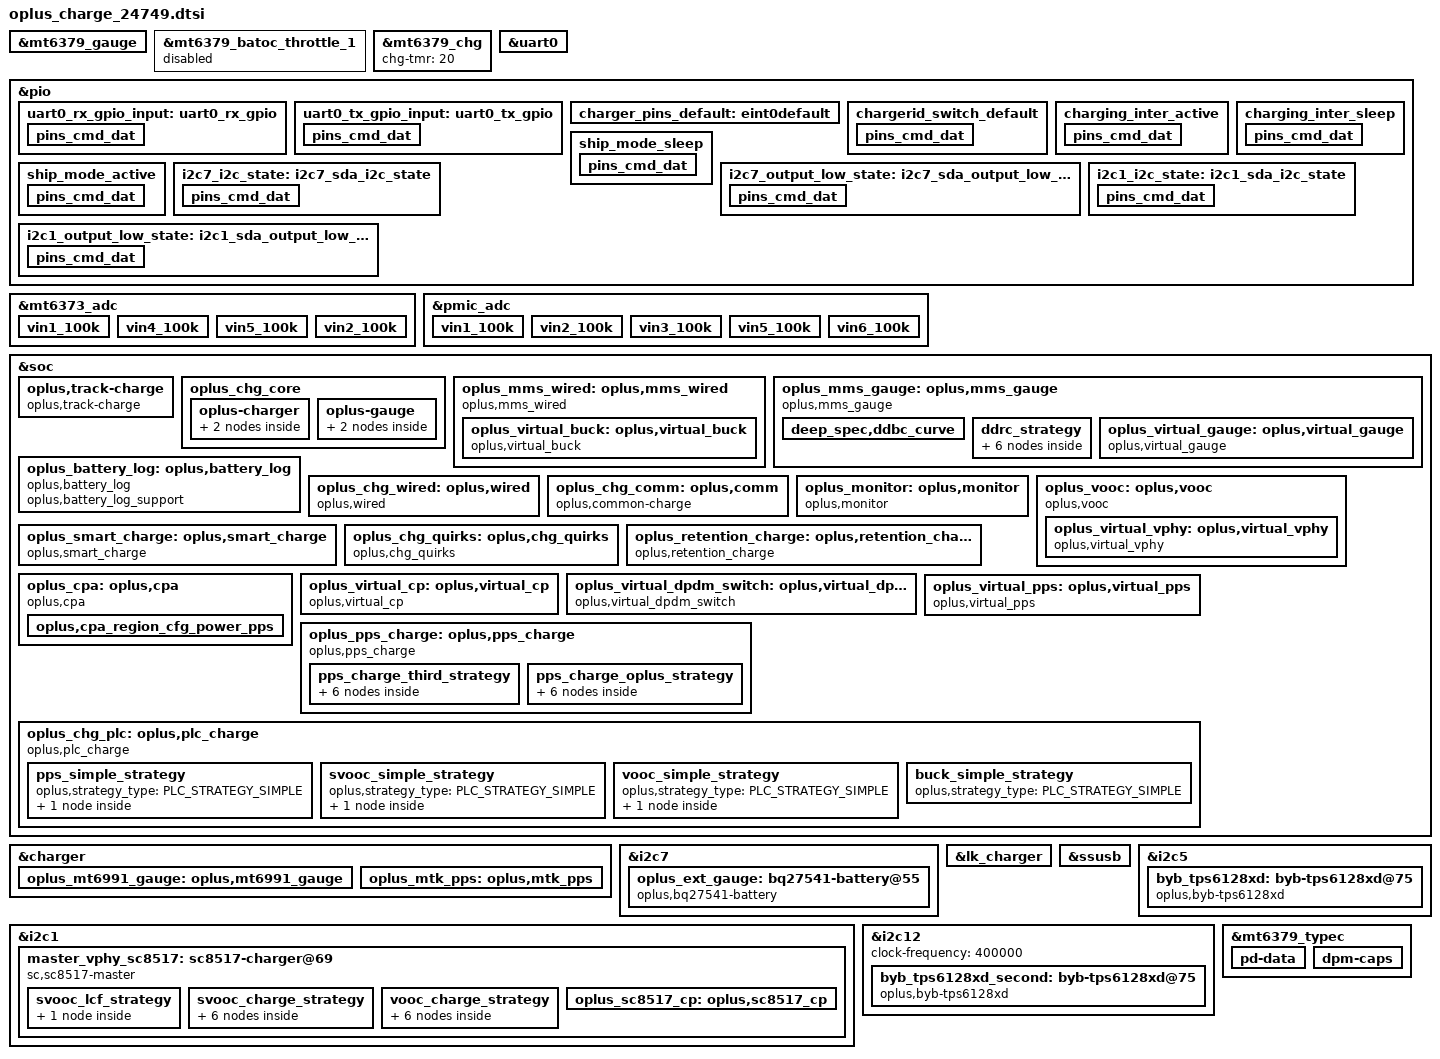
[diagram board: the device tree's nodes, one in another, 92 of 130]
// SPDX-License-Identifier: GPL-2.0-only
/*
* Copyright (C) 2021-2020 Oplus. All rights reserved.
*/
#include <dt-bindings/iio/mt635x-auxadc.h>
#include <dt-bindings/iio/adc/mediatek,mt6379_auxadc.h>  //???
#include <dt-bindings/pinctrl/mt6989-pinfunc.h>
#include <dt-bindings/pinctrl/mt65xx.h>
//#include "oplus_charge_22113.h"
#include "oplus_chg.h"

/* charge start */
//&regulator_vibrator{
//	status = "disabled";
//};

&mt6379_gauge {
	disable-mtkbattery = <(1)>;
	charger = <&mt6379_chg>;
};

&mt6379_batoc_throttle_1 {
	/* disable the batoc to avoid the issue of bat_oc interrup when the master BTB not connected */
	status = "disabled";
};

&mt6379_chg {
	chg-tmr = <20>;
};

&uart0 {
	pinctrl-names = "uart0_rx_gpio", "uart0_tx_gpio";
	pinctrl-0 = <&uart0_rx_gpio_input>;
	pinctrl-1 = <&uart0_tx_gpio_input>;
	status = "okay";

	txpin = <203>;
	rxpin = <204>;
};

&pio {
	uart0_rx_gpio_input: uart0_rx_gpio {
		pins_cmd_dat {
			pinmux = <PINMUX_GPIO204__FUNC_GPIO204>;
			input-enable;
			bias-disable;
		};
	};

	uart0_tx_gpio_input: uart0_tx_gpio {
		pins_cmd_dat {
			pinmux = <PINMUX_GPIO203__FUNC_GPIO203>;
			input-enable;
			bias-disable;
		};
	};
};

/* mt6373_adc is defined in mt6373.dtsi */
&mt6373_adc {
	vin1_100k {
		channel = <AUXADC_VIN1>;
		pures = <ADC_PURES_100K>;
	};
	vin4_100k {
		channel = <AUXADC_VIN4>;
		pures = <ADC_PURES_100K>;
	};
	vin5_100k {
		channel = <AUXADC_VIN5>;
		pures = <ADC_PURES_100K>;
	};
	vin2_100k {
		channel = <AUXADC_VIN2>;
		pures = <ADC_PURES_100K>;
	};
};

/* pmic_adc is defined in mt6363.dtsi */
&pmic_adc {
	vin1_100k {
		channel = <AUXADC_VIN1>;
		pures = <ADC_PURES_100K>;
	};
	vin2_100k {
		channel = <AUXADC_VIN2>;
		pures = <ADC_PURES_100K>;
	};
	vin3_100k {
		channel = <AUXADC_VIN3>;
		pures = <ADC_PURES_100K>;
	};
	vin5_100k {
		channel = <AUXADC_VIN5>;
		pures = <ADC_PURES_100K>;
	};
	vin6_100k {
		channel = <AUXADC_VIN6>;
		pures = <ADC_PURES_100K>;
	};
};

/* refer to udon oplus-chg-22803 */
&soc {
	oplus,track-charge {
		compatible = "oplus,track-charge";
		track,fast_chg_break_t_thd = <1400>;
		track,general_chg_break_t_thd = <300>;
		track,voocphy_type = <TRACK_AP_SINGLE_CP_VOOCPHY>;
		track,wired_max_power = <120000>;
		track,wired_fast_chg_scheme = <0>;
	};

};

&pio {
	charger_pins_default: eint0default {
	};

	chargerid_switch_default: chargerid_switch_default {
		pins_cmd_dat {
			pinmux = <PINMUX_GPIO81__FUNC_GPIO81>;
			bias-disable;
		};
	};

	charging_inter_active: charging_inter_active {
		pins_cmd_dat {
			pinmux = <PINMUX_GPIO83__FUNC_GPIO83>;
			input-enable;
			bias-pull-up;
		};
	};

	charging_inter_sleep: charging_inter_sleep {
		pins_cmd_dat {
			pinmux = <PINMUX_GPIO83__FUNC_GPIO83>;
			input-enable;
			bias-pull-up;
		};
	};

	ship_mode_sleep: ship_mode_sleep {
		pins_cmd_dat {
			pinmux = <PINMUX_GPIO216__FUNC_GPIO216>;
			output-low;
		};
	};

	ship_mode_active: ship_mode_active {
		pins_cmd_dat {
			pinmux = <PINMUX_GPIO216__FUNC_GPIO216>;
			output-high;
		};
	};
};

&soc {
	oplus_chg_core {
		oplus,chg_framework_v2;
		oplus,smart_charging_screenoff;
		oplus,chg_spec_version = <OPLUS_CHG_SPEC_VER_V3P7>;
		oplus,eco_region_list = /bits/ 8 <0x44>;
		oplus,common-charge-icl-support;

		oplus-charger {
			mtk_6991_groups: oplus,mtk_6991-groups {
				functions = <
					OPLUS_IC_FUNC_INIT
					OPLUS_IC_FUNC_EXIT
					OPLUS_IC_FUNC_REG_DUMP
					OPLUS_IC_FUNC_SMT_TEST
					OPLUS_IC_FUNC_BUCK_INPUT_PRESENT
					OPLUS_IC_FUNC_BUCK_INPUT_SUSPEND
					OPLUS_IC_FUNC_BUCK_INPUT_IS_SUSPEND
					OPLUS_IC_FUNC_BUCK_OUTPUT_SUSPEND
					OPLUS_IC_FUNC_BUCK_OUTPUT_IS_SUSPEND
					OPLUS_IC_FUNC_BUCK_SET_ICL
					OPLUS_IC_FUNC_BUCK_GET_ICL
					OPLUS_IC_FUNC_BUCK_SET_FCC
					OPLUS_IC_FUNC_BUCK_SET_FV
					OPLUS_IC_FUNC_BUCK_SET_ITERM
					OPLUS_IC_FUNC_BUCK_GET_INPUT_CURR
					OPLUS_IC_FUNC_BUCK_GET_INPUT_VOL
					OPLUS_IC_FUNC_OTG_BOOST_ENABLE
					OPLUS_IC_FUNC_BUCK_GET_CC_ORIENTATION
					OPLUS_IC_FUNC_BUCK_GET_CHARGER_TYPE
					OPLUS_IC_FUNC_BUCK_RERUN_BC12
					OPLUS_IC_FUNC_BUCK_QC_DETECT_ENABLE
					OPLUS_IC_FUNC_BUCK_SET_QC_CONFIG
					OPLUS_IC_FUNC_BUCK_SET_PD_CONFIG
					OPLUS_IC_FUNC_GET_SHUTDOWN_SOC
					OPLUS_IC_FUNC_BACKUP_SOC
					OPLUS_IC_FUNC_GET_TYPEC_MODE
					OPLUS_IC_FUNC_SET_TYPEC_MODE
					OPLUS_IC_FUNC_GET_TYPEC_ROLE
					OPLUS_IC_FUNC_GET_OTG_ENABLE
					OPLUS_IC_FUNC_BUCK_GET_HW_DETECT
					OPLUS_IC_FUNC_SET_USB_DISCHG_ENABLE
					OPLUS_IC_FUNC_GET_USB_DISCHG_STATUS
					OPLUS_IC_FUNC_IS_OPLUS_SVID
					OPLUS_IC_FUNC_BUCK_GET_USB_BTB_TEMP
					OPLUS_IC_FUNC_BUCK_GET_BATT_BTB_TEMP
					OPLUS_IC_FUNC_BUCK_SHIPMODE_ENABLE
					OPLUS_IC_FUNC_BUCK_SET_AICL_POINT
					OPLUS_IC_FUNC_SET_OTG_BOOST_CURR_LIMIT
					OPLUS_IC_FUNC_SET_OTG_BOOST_VOL
					OPLUS_IC_FUNC_BUCK_GET_FV
					OPLUS_IC_FUNC_BUCK_GET_TYPEC_STATE
					OPLUS_IC_FUNC_WLS_BOOST_ENABLE
					OPLUS_IC_FUNC_SET_WLS_BOOST_VOL
					OPLUS_IC_FUNC_SET_WLS_BOOST_CURR_LIMIT
					OPLUS_IC_FUNC_BUCK_WLS_INPUT_SUSPEND
					OPLUS_IC_FUNC_BUCK_SET_WLS_ICL
					OPLUS_IC_FUNC_BUCK_GET_WLS_ICL
					OPLUS_IC_FUNC_BUCK_GET_WLS_INPUT_CURR
					OPLUS_IC_FUNC_BUCK_GET_WLS_INPUT_VOL
					OPLUS_IC_FUNC_BUCK_WLS_AICL_ENABLE
					OPLUS_IC_FUNC_BUCK_WLS_AICL_RERUN
					OPLUS_IC_FUNC_BUCK_DIS_INSERT_DETECT
					OPLUS_IC_FUNC_BUCK_GET_USB_AICL_ENHANCE
				>;
				virqs = <
					OPLUS_IC_VIRQ_ERR
					OPLUS_IC_VIRQ_CC_DETECT
					OPLUS_IC_VIRQ_PLUGIN
					OPLUS_IC_VIRQ_CC_CHANGED
					OPLUS_IC_VIRQ_CHG_TYPE_CHANGE
					OPLUS_IC_VIRQ_OTG_ENABLE
					OPLUS_IC_VIRQ_SVID
					OPLUS_IC_VIRQ_TYPEC_STATE
				>;
			};
			byb_tps6128xd_groups: oplus,byb-tps6128xd-groups {

				functions = <
					OPLUS_IC_FUNC_INIT
					OPLUS_IC_FUNC_EXIT
					OPLUS_IC_FUNC_REG_DUMP
				>;
				virqs = <
					OPLUS_IC_VIRQ_ERR
				>;
			};
		};

		oplus-gauge {
			bq27541_groups: oplus,bq27541_groups {
				functions = <
					OPLUS_IC_FUNC_INIT
					OPLUS_IC_FUNC_EXIT
					OPLUS_IC_FUNC_REG_DUMP
					OPLUS_IC_FUNC_SMT_TEST
					OPLUS_IC_FUNC_GAUGE_GET_BATT_VOL
					OPLUS_IC_FUNC_GAUGE_GET_BATT_MAX
					OPLUS_IC_FUNC_GAUGE_GET_BATT_MIN
					OPLUS_IC_FUNC_GAUGE_GET_BATT_CURR
					OPLUS_IC_FUNC_GAUGE_GET_BATT_TEMP
					OPLUS_IC_FUNC_GAUGE_GET_BATT_SOC
					OPLUS_IC_FUNC_GAUGE_GET_BATT_FCC
					OPLUS_IC_FUNC_GAUGE_GET_BATT_CC
					OPLUS_IC_FUNC_GAUGE_GET_BATT_RM
					OPLUS_IC_FUNC_GAUGE_GET_BATT_SOH
					OPLUS_IC_FUNC_GAUGE_GET_BATT_AUTH
					OPLUS_IC_FUNC_GAUGE_GET_BATT_HMAC
					OPLUS_IC_FUNC_GAUGE_SET_BATT_FULL
					OPLUS_IC_FUNC_GAUGE_UPDATE_DOD0
					OPLUS_IC_FUNC_GAUGE_UPDATE_SOC_SMOOTH
					OPLUS_IC_FUNC_GAUGE_GET_CB_STATUS
					OPLUS_IC_FUNC_GAUGE_GET_BATT_NUM
					OPLUS_IC_FUNC_GAUGE_GET_DEVICE_TYPE
					OPLUS_IC_FUNC_GAUGE_GET_DEVICE_TYPE_FOR_VOOC
					OPLUS_IC_FUNC_GAUGE_GET_BATT_FCC
					OPLUS_IC_FUNC_GAUGE_GET_BATT_FC
					OPLUS_IC_FUNC_GAUGE_GET_BATT_QM
					OPLUS_IC_FUNC_GAUGE_GET_BATT_PD
					OPLUS_IC_FUNC_GAUGE_GET_BATT_RCU
					OPLUS_IC_FUNC_GAUGE_GET_BATT_RCF
					OPLUS_IC_FUNC_GAUGE_GET_BATT_FCU
					OPLUS_IC_FUNC_GAUGE_GET_BATT_FCF
					OPLUS_IC_FUNC_GAUGE_GET_BATT_SOU
					OPLUS_IC_FUNC_GAUGE_GET_BATT_DO0
					OPLUS_IC_FUNC_GAUGE_GET_BATT_DOE
					OPLUS_IC_FUNC_GAUGE_GET_BATT_TRM
					OPLUS_IC_FUNC_GAUGE_GET_BATT_PC
					OPLUS_IC_FUNC_GAUGE_GET_BATT_QS
					OPLUS_IC_FUNC_GAUGE_IS_SUSPEND
					OPLUS_IC_FUNC_GAUGE_GET_BCC_PARMS
					OPLUS_IC_FUNC_GAUGE_FASTCHG_UPDATE_BCC_PARMS
					OPLUS_IC_FUNC_GAUGE_GET_PREV_BCC_PARMS
					OPLUS_IC_FUNC_GAUGE_SET_BCC_PARMS
					OPLUS_IC_FUNC_GAUGE_SET_PROTECT_CHECK
					OPLUS_IC_FUNC_GAUGE_GET_AFI_UPDATE_DONE
					OPLUS_IC_FUNC_GAUGE_CHECK_RESET
					OPLUS_IC_FUNC_GAUGE_SET_RESET
					OPLUS_IC_FUNC_GAUGE_GET_DEVICE_TYPE_FOR_BCC
					OPLUS_IC_FUNC_GAUGE_GET_DOD0
					OPLUS_IC_FUNC_GAUGE_GET_DOD0_PASSED_Q
					OPLUS_IC_FUNC_GAUGE_GET_QMAX
					OPLUS_IC_FUNC_GAUGE_GET_QMAX_PASSED_Q
					OPLUS_IC_FUNC_GAUGE_GET_REG_INFO
					OPLUS_IC_FUNC_GAUGE_GET_CALIB_TIME
					OPLUS_IC_FUNC_GAUGE_GET_DEEP_DISCHG_COUNT
					OPLUS_IC_FUNC_GAUGE_SET_DEEP_DISCHG_COUNT
					OPLUS_IC_FUNC_GAUGE_GET_DEEP_TERM_VOLT
					OPLUS_IC_FUNC_GAUGE_SET_DEEP_TERM_VOLT
					OPLUS_IC_FUNC_GAUGE_SET_SILI_SPARE_POWER
					OPLUS_IC_FUNC_GAUGE_GET_SILI_SIMULATE_TERM_VOLT
					OPLUS_IC_FUNC_GAUGE_GET_SILI_IC_ALG_TERM_VOLT
					OPLUS_IC_FUNC_GAUGE_SET_SILI_IC_ALG_CFG
					OPLUS_IC_FUNC_GAUGE_GET_SILI_IC_ALG_DSG_ENABLE
					OPLUS_IC_FUNC_GAUGE_SET_SILI_IC_ALG_TERM_VOLT
					OPLUS_IC_FUNC_GAUGE_GET_SILI_ALG_APPLICATION_INFO
					OPLUS_IC_FUNC_GAUGE_GET_SILI_LIFETIME_STATUS
					OPLUS_IC_FUNC_GAUGE_GET_SILI_LIFETIME_INFO
					OPLUS_IC_FUNC_GAUGE_SET_CALIB_TIME
					OPLUS_IC_FUNC_GAUGE_SET_LAST_CC
					OPLUS_IC_FUNC_GAUGE_GET_LAST_CC
					OPLUS_IC_FUNC_GAUGE_GET_BATT_SN
					OPLUS_IC_FUNC_GAUGE_GET_MANU_DATE
					OPLUS_IC_FUNC_GAUGE_GET_FIRST_USAGE_DATE
					OPLUS_IC_FUNC_GAUGE_SET_FIRST_USAGE_DATE
					OPLUS_IC_FUNC_GAUGE_GET_UI_CC
					OPLUS_IC_FUNC_GAUGE_SET_UI_CC
					OPLUS_IC_FUNC_GAUGE_GET_UI_SOH
					OPLUS_IC_FUNC_GAUGE_SET_UI_SOH
					OPLUS_IC_FUNC_GAUGE_GET_USED_FLAG
					OPLUS_IC_FUNC_GAUGE_SET_USED_FLAG
					OPLUS_IC_FUNC_GAUGE_SET_SEAL_FLAG
					OPLUS_IC_FUNC_GAUGE_GET_DEC_FG_TYPE
					OPLUS_IC_FUNC_GAUGE_GET_DEC_CV_SOH
					OPLUS_IC_FUNC_GAUGE_SET_VCT
					OPLUS_IC_FUNC_GAUGE_GET_VCT
					OPLUS_IC_FUNC_GAUGE_GET_GAUGE_R_INFO
				>;
				virqs = <
					OPLUS_IC_VIRQ_ERR
					OPLUS_IC_VIRQ_OFFLINE
					OPLUS_IC_VIRQ_RESUME
				>;
			};

			mt6991_gauge_groups: oplus,mt6991_gauge_groups {
				functions = <
					OPLUS_IC_FUNC_INIT
					OPLUS_IC_FUNC_EXIT
					OPLUS_IC_FUNC_GAUGE_GET_SUBBOARD_TEMP
				>;
				virqs = <
					OPLUS_IC_VIRQ_ERR
				>;
			};
		};
	};
};

&charger {
	io-channels = <&pmic_adc (ADC_PURES_100K_MASK | AUXADC_VIN5)>,
			<&pmic_adc (ADC_PURES_100K_MASK | AUXADC_VIN6)>,
			<&pmic_adc (ADC_PURES_100K_MASK | AUXADC_VIN1)>,
			<&pmic_adc (ADC_PURES_100K_MASK | AUXADC_VIN2)>,
			<&mt6373_adc AUXADC_VIN2>;
	io-channel-names = "master_cp_temp", "auxadc6_usb_btb_temp",
			   "auxadc1-ntc_sub_bat_tem",
			   "auxadc5_batt_btb_temp", "slave_cp_temp";

	pinctrl-names = "default";
	pinctrl-0 = <&charger_pins_default>;
	oplus,support_ntc_01c_precision;
	oplus,support_subboard_ntc;
	max_charger_voltage = <15000000>;
	oplus,usb_aicl_enhance;
	oplus,low_batt_otg_boost_curr_ua = <500000>;

	oplus,ic_type = <OPLUS_CHG_IC_BUCK>;
	oplus,ic_index = <0>;

	oplus_mt6991_gauge: oplus,mt6991_gauge {
		oplus,ic_type = <OPLUS_CHG_IC_GAUGE>;
		oplus,ic_index = <1>;
	};
};
&i2c7 {
	status = "okay";
	clock-frequency = <100000>;

	oplus_ext_gauge: bq27541-battery@55 {
		status = "okay";
		compatible = "oplus,bq27541-battery";
		reg = <0x55 0>;
		qcom,modify-soc-smooth;
		qcom,modify-soc-calibration;
		oplus,remove_iterm_taper;
		qcom,batt_bq28z610; /* TODO: maybe need update.*/
		oplus,fcc_too_small_check_support;
		qcom,sha1_key_index = <1>;
		oplus,batt_num = <2>;
		oplus,ic_type = <OPLUS_CHG_IC_GAUGE>;
		oplus,ic_index = <0>;
		oplus,bq28z610_afi_buf = /bits/ 8 <
		/* checksum data_len data+ */
			0xD8 0x04 0xf4 0x46 0xED 0x00 /* Charge Term Taper Current 217mA */
			0x24 0x03 0x90 0x45 0x06 /* MIN_RES_POINTS 6 */
			0x24 0x03 0x91 0x45 0x05 /* RA_MAX_DELTA 5 */
			0xd8 0x03 0xe8 0x45 0xfa /* SOH_LOAD_RATE 250 */
			0x2 0x04 0x94 0x45 0x25 0xff /* RES_PARA_FILTER 65317 */
			0x3d 0x04 0x96 0x45 0xed 0xfa /* RA_PARA_FILTER 64237 */
			0xeb 0x03 0x89 0x45 0x46 /* MIN_DOD_RES 70 */
			0x73 0x04 0x8e 0x45 0xb6 0x3 /* RA_PARA_FILTER 950 */
		>;
		};
	};

&lk_charger {
	is_support_mt6379;
	charger_by_bidirection;
	support_external_gauge_bq28z610;
	external_gauge_type = <EXTERNAL_GAUGE_TYPE_BQ28Z719>;
	support_tuv_authentication;
	high-temp-scheme;
	support_sdp_screenoff;
	use_extern_gauge;
	sub_board_temp_support;
	over_high_temp_thr = <60>;
	sub_board_adc_channel = <18>; /* AUXADC_VIN1 */
	sub_board_adc_pull_up_voltage = <1840>;
	support_battery_type = <7>;
	batt_num = <2>;
	support_quickboot_charge;

	/* mt6991 start */
	led-brightness = <102>;
	/* mt6991, such as max_charger_voltage to max-charger-voltage */
	max-charger-voltage = <15000000>;
	boot-battery-voltage = <3350000>;
	usb-charger-current = <500000>;
	ac-charger-current = <2050000>;
	ac-charger-input-current = <1500000>;
	non-std-ac-charger-current = <750000>;
	charging-host-charger-current = <1500000>;
	ta-ac-charger-current = <1500000>;
	pd-charger-current = <500000>;
	/* mt6991 end */
	/* for silicon battery */
	is_silicon_battery;
	max-term-voltage-mv = <3300>;
	min-term-voltage-mv = <3000>;
	dcp-boot-thd-inc-mv = <(-100)>;
	cdp-boot-thd-inc-mv = <(50)>;
	sdp-boot-thd-inc-mv = <(50)>;
	wls-boot-thd-inc-mv = <(50)>;
	nochg-boot-thd-inc-mv = <(50)>;
	max-boot-thd-mv = <(3350)>;
	min-boot-thd-mv = <(3150)>;
	dcp-max-boot-thd-mv = <(3350)>;
	dcp-min-boot-thd-mv = <(3050)>;
	prechg1-thd-mv = <3000>;
	prechg1-current-ma = <500>;/* dual-cell configuration value is twice the ibat-ma */
	temp-low-inc1 = <500>; /* < -20 */
	temp-low-inc2 = <500>; /* -20 ~ -10 */
	temp-low-inc3 = <500>; /* -10 ~ 0 */
	temp-low-inc4 = <100>; /* 0 ~ 20 */
	temp-low-inc5 = <0>; /* > 20 */
	/* silicon battery end */
};

&i2c7 {
	pinctrl-names = "i2c-state", "output-low-state";
	pinctrl-0 = <&i2c7_i2c_state>;
	pinctrl-1 = <&i2c7_output_low_state>;
};
&pio {
	i2c7_i2c_state: i2c7_sda_i2c_state {
		pins_cmd_dat {
			pinmux = <PINMUX_GPIO120__FUNC_SCL7>,
			<PINMUX_GPIO121__FUNC_SDA7>;
			bias-pull-up;
		};
	};
	i2c7_output_low_state: i2c7_sda_output_low_state {
		pins_cmd_dat {
			pinmux = <PINMUX_GPIO120__FUNC_GPIO120>,
			<PINMUX_GPIO121__FUNC_GPIO121>;
			output-low;
		};
	};
};

/* for pd common charger */
&ssusb {
		usb-psy-name = "mtk-master-charger";
		typec-name = "rt-pd-manager";
		typec-port-name = "port0";
};

&i2c5 {
		mediatek,fifo-use-polling;
		mediatek,request-cpu-qos;
};

&soc {
	oplus_mms_wired: oplus,mms_wired {
		compatible = "oplus,mms_wired";
		oplus,buck_ic = <&oplus_virtual_buck>;
		oplus,voocphy_ic = <&oplus_virtual_vphy>;

		oplus,adc_info_name = "100k_1840mv";
		oplus_spec,usbtemp_batttemp_gap = <12>;
		high-temp-scheme;

		/* support for V2.0 usbtemp protect. */
		oplus,support_usbtemp_protect_v2;
		oplus_spec,usbtemp_batt_temp_low = <50>;
		oplus_spec,usbtemp_batt_temp_high = <50>;
		oplus_spec,usbtemp_batt_temp_over_hot = <60>;
		oplus_spec,usbtemp_ntc_temp_low = <57>;
		oplus_spec,usbtemp_ntc_temp_high = <69>;
		oplus_spec,usbtemp_temp_gap_low_with_batt_temp = <7>;
		oplus_spec,usbtemp_temp_gap_with_batt_temp_in_over_hot = <15>;
		oplus_spec,usbtemp_temp_gap_high_with_batt_temp = <12>;
		oplus_spec,usbtemp_temp_gap_low_without_batt_temp = <12>;
		oplus_spec,usbtemp_temp_gap_high_without_batt_temp = <24>;
		oplus_spec,usbtemp_rise_fast_temp_low = <3>;
		oplus_spec,usbtemp_rise_fast_temp_high = <3>;
		oplus_spec,usbtemp_rise_fast_temp_count_low = <30>;
		oplus_spec,usbtemp_rise_fast_temp_count_high = <20>;
		oplus_spec,usbtemp_cool_down_ntc_low = <54>;
		oplus_spec,usbtemp_cool_down_ntc_high = <65>;
		oplus_spec,usbtemp_cool_down_gap_low = <12>;
		oplus_spec,usbtemp_cool_down_gap_high = <20>;
		oplus_spec,usbtemp_cool_down_recover_ntc_low = <48>;
		oplus_spec,usbtemp_cool_down_recover_ntc_high = <60>;
		oplus_spec,usbtemp_cool_down_recover_gap_low = <6>;
		oplus_spec,usbtemp_cool_down_recover_gap_high = <15>;
		oplus_spec,usbtemp_otg_cc_boot_current_limit = <1300000>;

		oplus_virtual_buck: oplus,virtual_buck {
			compatible = "oplus,virtual_buck";
			oplus,buck_ic = <&charger &byb_tps6128xd &byb_tps6128xd_second>;
			oplus,buck_ic_index = <0 1 2>;
			oplus,buck_ic_current_ratio = <100 0 0>;
			oplus,buck_ic_connect = <OPLUS_CHG_IC_CONNECT_PARALLEL>;
			oplus,main_charger = <0>;
			oplus,buck_ic_func_group = <&mtk_6991_groups &byb_tps6128xd_groups &byb_tps6128xd_groups>;

			oplus,ic_type = <OPLUS_CHG_IC_VIRTUAL_BUCK>;
			oplus,ic_index = <0>;

			/* SHIP_MODE_ON */
			oplus,ship-gpio = <&pio 216 0x00>;

			pinctrl-names = "ship_active", "ship_sleep";
			pinctrl-0 = <&ship_mode_active>;
			pinctrl-1 = <&ship_mode_sleep>;

			io-channels = <&mt6373_adc AUXADC_VIN4>, <&mt6373_adc AUXADC_VIN5>;
			io-channel-names = "usb_temp_adc_l", "usb_temp_adc_r";

			oplus,uart_tx-gpio = <&pio 203 0x00>;
			oplus,uart_rx-gpio = <&pio 204 0x00>;
		};
	};

	oplus_mms_gauge: oplus,mms_gauge {
		compatible = "oplus,mms_gauge";
		oplus,gauge_ic = <&oplus_virtual_gauge>;
		oplus,topic-update-interval = <10000>;
		oplus,support_subboard_ntc;

		deep_spec,support;
		deep_spec,uv_thr = <3000>;
		deep_spec,count_thr = <50>;
		deep_spec,vbat_soc = <20>;
		deep_spec,count_step = <0 10 0
					350 12 1
					450 15 2
					530 20 3>;
		deep_spec,term_coeff = <3000 800 3
					3050 900 5
					3060 900 5
					3100 950 7
					3150 950 7
					3200 1050 9
					3300 1200 10>;
		deep_spec,ddrc_strategy_name = "ddrc_curve";
		deep_spec,volt_step = <20>;
		deep_spec,ddbc_curve {
			oplus,temp_type = <OPLUS_STRATEGY_USE_BATT_TEMP>;
			oplus,temp_range = <(-100) 50 200>;
			deep_spec,ddbc_temp_cold =   <500   3250 5
						      10000 3200 2>;
			deep_spec,ddbc_temp_cool =   <500   3250 5
						      10000 3200 2>;
			deep_spec,ddbc_temp_normal = <500   3350 5
						      10000 3300 2>;
			deep_spec,ddbc_temp_warm =   <500   3350 5
						      10000 3300 2>;
		};
		ddrc_strategy {
			oplus,temp_type = <OPLUS_STRATEGY_USE_BATT_TEMP>;
			oplus,ratio_range = <20 30 50 70 90>;
			oplus,temp_range = <(-50) 100 350>;
			strategy_ratio_range_min { /* 0 ~ 0.2 */
				strategy_temp_cold =	<0    3000 3060 0
							 400  3000 3060 1
							 800  3000 3060 2
							 1200 3100 3100 3
							 1600 3200 3200 4
							 2000 3300 3300 5>;
				strategy_temp_cool =	<0    3000 3060 0
							 15   3000 3060 1
							 500  3000 3060 2
							 1000 3100 3100 3
							 1500 3200 3200 4
							 2000 3300 3300 5>;
				strategy_temp_normal =	<0    3150 3150 0
							 15   3150 3150 1
							 500  3150 3150 2
							 1000 3200 3200 3
							 1500 3300 3300 4>;
				strategy_temp_warm =	<0    3150 3150 0
							 15   3150 3150 1
							 500  3150 3150 2
							 1000 3200 3200 3
							 1500 3300 3300 4>;
			};
			strategy_ratio_range_low { /* 0.2 ~ 0.3 */
				strategy_temp_cold =	<0    3000 3060 0
							 300  3000 3060 1
							 600  3000 3060 2
							 900  3100 3100 3
							 1200 3200 3200 4
							 1600 3300 3300 5>;
				strategy_temp_cool =	<0    3000 3060 0
							 15   3000 3060 1
							 400  3000 3060 2
							 800  3100 3100 3
							 1200 3200 3200 4
							 1600 3300 3300 5>;
				strategy_temp_normal =	<0    3150 3150 0
							 15   3150 3150 1
							 400  3150 3150 2
							 800  3200 3200 3
							 1200 3300 3300 4>;
				strategy_temp_warm =	<0    3150 3150 0
							 15   3150 3150 1
							 400  3150 3150 2
							 800  3200 3200 3
							 1200 3300 3300 4>;
			};
			strategy_ratio_range_mid_low { /* 0.3 ~ 0.5 */
				strategy_temp_cold =	<0    3000 3060 0
							 200  3000 3060 1
							 400  3000 3060 2
							 600  3100 3100 3
							 900  3200 3200 4
							 1200  3300 3300 5>;
				strategy_temp_cool =	<0    3000 3060 0
							 15   3000 3060 1
							 300  3000 3060 2
							 600  3100 3100 3
							 900  3200 3200 4
							 1200  3300 3300 5>;
				strategy_temp_normal =	<0    3150 3150 0
							 15   3150 3150 1
							 300  3150 3150 2
							 600  3200 3200 3
							 900  3300 3300 4>;
				strategy_temp_warm =	<0    3150 3150 0
							 15   3150 3150 1
							 300  3150 3150 2
							 600  3200 3200 3
							 900  3300 3300 4>;
			};
			strategy_ratio_range_mid { /* 0.5 ~ 0.7 */
				strategy_temp_cold =	<0    3000 3060 0
							 100  3000 3060 1
							 300  3000 3060 2
							 500  3100 3100 3
							 700  3200 3200 4
							 900  3300 3300 5>;
				strategy_temp_cool =	<0   3000 3060 0
							 100 3000 3060 1
							 300 3100 3100 2
							 600 3200 3200 3
							 900 3300 3300 4>;
				strategy_temp_normal =	<0   3150 3150 0
							 100 3150 3150 1
							 300 3200 3200 2
							 600 3300 3300 3>;
				strategy_temp_warm =	<0   3150 3150 0
							 100 3150 3150 1
							 300 3200 3200 2
							 600 3300 3300 3>;
			};
			strategy_ratio_range_mid_high { /* 0.7 ~ 0.9 */
				strategy_temp_cold =	<0    3000 3060 0
							 50   3000 3060 1
							 100  3000 3060 2
							 150  3100 3100 3
							 300  3200 3200 4
							 500  3300 3300 5>;
				strategy_temp_cool =	<0    3000 3060 0
							 50   3000 3060 1
							 100  3100 3100 2
							 150  3200 3200 3
							 300  3300 3300 4>;
				strategy_temp_normal =	<0    3150 3150 0
							 50   3150 3150 1
							 100  3200 3200 2
							 150  3300 3300 3>;
				strategy_temp_warm =	<0    3150 3150 0
							 50   3150 3150 1
							 100  3200 3200 2
							 150  3300 3300 3>;
			};
			strategy_ratio_range_high { /* 0.9 ~ 1 */
				strategy_temp_cold =	<0    3000 3060 0
							 50   3000 3060 1
							 100  3000 3060 2
							 150  3100 3100 3
							 300  3200 3200 4
							 500  3300 3300 5>;
				strategy_temp_cool =	<0    3000 3060 0
							 50   3000 3060 1
							 100  3100 3100 2
							 150  3200 3200 3
							 300  3300 3300 4>;
				strategy_temp_normal =	<0    3150 3150 0
							 50   3150 3150 1
							 100  3200 3200 2
							 150  3300 3300 3>;
				strategy_temp_warm =	<0    3150 3150 0
							 50   3150 3150 1
							 100  3200 3200 2
							 150  3300 3300 3>;
			};
		};
		oplus_virtual_gauge: oplus,virtual_gauge {
			compatible = "oplus,virtual_gauge";
			oplus,gauge_ic = <&oplus_ext_gauge &oplus_mt6991_gauge>;
			oplus,gauge_ic_index = <0 1>;
			oplus,gauge_ic_func_group = <&bq27541_groups &mt6991_gauge_groups>;
			oplus,batt_capacity_mah = <7000>;
			oplus,ic_type = <OPLUS_CHG_IC_VIRTUAL_GAUGE>;
			oplus,ic_index = <0>;
		};
	};
};

&soc {
	oplus_battery_log: oplus,battery_log {
		compatible = "oplus,battery_log";

		oplus,battery_log_support;
	};

	oplus_chg_wired: oplus,wired {
		compatible = "oplus,wired";

		oplus,vooc-support;

		oplus_spec,vbatt_pdqc_to_5v_thr = <5100>;
		oplus_spec,vbatt_pdqc_to_9v_thr = <5000>;
		oplus_spec,pd-iclmax-ma = <2000>;
		oplus_spec,qc-iclmax-ma = <2000>;
		oplus_spec,non-standard-ibatmax-ma = <500>;
		oplus_spec,input-power-mw = <
			500		/* OPLUS_WIRED_CHG_MODE_UNKNOWN */
			2500		/* OPLUS_WIRED_CHG_MODE_SDP */
			7500		/* OPLUS_WIRED_CHG_MODE_CDP */
			10000		/* OPLUS_WIRED_CHG_MODE_DCP */
			15000		/* OPLUS_WIRED_CHG_MODE_VOOC */
			13500		/* OPLUS_WIRED_CHG_MODE_QC */
			13500		/* OPLUS_WIRED_CHG_MODE_PD */
		>;
		oplus_spec,led_on-fccmax-ma = <0 602 3014 3300 3300 3300 3300 1000 0>;
		oplus_spec,fccmax-ma-lv = <
			0 602 2200 2200 2200 2200 2200 2200 0	/* OPLUS_WIRED_CHG_MODE_UNKNOWN */
			0 600  600  600  600  600  600  600  0	/* OPLUS_WIRED_CHG_MODE_SDP */
			0 602 1600 1600 1600 1600 1600 1600 0	/* OPLUS_WIRED_CHG_MODE_CDP */
			0 602 2200 2200 2200 2200 2200 2200 0	/* OPLUS_WIRED_CHG_MODE_DCP */
			0 602 3014 3300 3300 3300 3300 3300 0	/* OPLUS_WIRED_CHG_MODE_VOOC */
			0 602 2860 2860 2860 2860 2860 2860 0	/* OPLUS_WIRED_CHG_MODE_QC */
			0 602 2860 2860 2860 2860 2860 2860 0	/* OPLUS_WIRED_CHG_MODE_PD */
		>;
		oplus_spec,fccmax-ma-hv = <
			0 484  968 2200 2200 2200 2200 2200 0	/* OPLUS_WIRED_CHG_MODE_UNKNOWN */
			0 600  600  600  600  600  600  600 0	/* OPLUS_WIRED_CHG_MODE_SDP */
			0 602  1206 1600 1600 1600 1600 600 0	/* OPLUS_WIRED_CHG_MODE_CDP */
			0 602  1206 1808 2200 2200 2200 1000 0	/* OPLUS_WIRED_CHG_MODE_DCP */
			0 602  1206 1808 3014 3300 3300 1000 0	/* OPLUS_WIRED_CHG_MODE_VOOC */
			0 602  1206 1808 2860 2860 2860 1000 0	/* OPLUS_WIRED_CHG_MODE_QC */
			0 602  1206 1808 2860 2860 2860 1000 0	/* OPLUS_WIRED_CHG_MODE_PD */
		>;
		oplus_spec,cool_down_sale_pdqc_vol_mv = <9000>;
		oplus_spec,cool_down_sale_pdqc_curr_ma = <1200>;
		oplus_spec,cool_down_pdqc_vol_mv = <9000 9000 9000>;
		oplus_spec,cool_down_pdqc_curr_ma = <1200 1500 2000>;
		oplus_spec,cool_down_vooc_curr_ma = <1500 1500 2000 2500 3000 3500>;
		oplus_spec,cool_down_normal_curr_ma = <1200 1500 2000>;

		oplus_spec,vbus_ov_thr_mv = <11000 11000>;
		oplus_spec,vbus_uv_thr_mv = <4300 4300>;

		/* first data is strategy used temp type */
		oplus,vooc_strategy_name = "cgcl";
		oplus,vooc_strategy_data = <OPLUS_STRATEGY_USE_BATT_TEMP
					    0   350 3600 1 0
					    330 370 3200 2 0
					    350 440 2200 2 1>;
	};

	oplus_chg_comm: oplus,comm {
		compatible = "oplus,common-charge";
		oplus_spec,dec_step = <20>;
		oplus_spec,dec-vol-cc-full-thr = <0 400 600 800 1000 1200>;
		oplus_spec,dec-vol-fv-full-mv = <0 20 20 40 40 40>;
		oplus_spec,batt-them-thr = <(-100) 0 50 120 160 350 450 530>;
		oplus_spec,iterm-ma = <178>; /* 2220*0.05+10 */
		oplus_spec,removed_bat_decidegc = <390>; /*-39 degree*/
		oplus_spec,fv-mv = <4500 4500 4500 4500 4500 4500 4475 4130 4130>;
		oplus_spec,sw-fv-mv = <4450 4450 4450 4450 4450 4450 4425 4080 4080>;
		oplus_spec,hw-fv-inc-mv = <0 18 18 18 18 18 18 18 0>;
		oplus_spec,sw-over-fv-mv = <4510 4510 4510 4510 4510 4510 4485 4140 4140>;
		oplus_spec,sw-over-fv-dec-mv = <8>;
		oplus_spec,non-standard-sw-fv-mv = <3930>;
		oplus_spec,non-standard-fv-mv = <3980>;
		oplus_spec,non-standard-hw-fv-inc-mv = <18>;
		oplus_spec,non-standard-sw-over-fv-mv = <3990>;
		oplus_spec,non-standard-vbatdet-mv = <3680>;
		oplus_spec,wired-vbatdet-mv = <0 4200 4300 4400 4400 4400 4375 4030 0>;
		oplus_spec,wls-vbatdet-mv = <0 4210 4310 4410 4410 4410 4385 4030 0>;
		oplus_spec,fcc-gear-thr-mv = <4180>;
		oplus_spec,fcc-gear-shake-mv = <550 550 350 200 200 150 150 100 100>;
		oplus_spec,vbatt-ov-thr-mv = <4600>;

		oplus_spec,full_pre_ffc_judge;
		oplus_spec,full-pre-ffc-mv = <4495>;
		oplus_spec,ffc-temp-thr = <120 210 350 440>;
		oplus_spec,wired-ffc-step-max = <2>;
		oplus_spec,wired-ffc-fv-mv = <4590 4590>;
		oplus_spec,wired-ffc-fv-cutoff-mv = <4550 4525 4490
						     4520 4505 4475>;

		oplus_spec,wired-ffc-fcc-ma = <1100 1100 1100
					         700 700 700>;
		oplus_spec,wired-ffc-fcc-cutoff-ma = <400 400 400
						      200 200 200>;

		oplus_spec,drop_soc_2_temp_ladder = <(-50) 0 0 0 0 0 0 0 0 0>;
		oplus_spec,volt_diff_ladder_of_drop_soc_2 = <20 50 0 0 0 0 0 0 0 0>;
		oplus_spec,keep_soc_2_temp_ladder = <(-200) (-50) 0 0 0 0 0 0 0 0>;
		oplus_spec,volt_diff_ladder_of_keep_soc_2 = <10 20 30 0 0 0 0 0 0 0>;
		oplus_spec,back_rm_of_drop_soc_2 = <60>;
		oplus_spec,back_rm_of_drop_soc_1 = <60>;
		oplus_spec,load_current_of_drop_soc_2 = <500>;
		oplus_spec,load_current_of_drop_soc_1 = <1000>;
		oplus_spec,current_limit_of_drop_soc_2 = <350>;
		oplus_spec,volt_of_fast_drop_soc_1 = <3000>;
		oplus_spec,support_uisoc_low_battery_control;
		oplus_spec,support_gauge_r_track;

		oplus_spec,wls-ffc-step-max = <2>;
		oplus_spec,wls-ffc-fv-mv = <4630 4630>;
		oplus_spec,wls-ffc-fv-cutoff-mv = <4545 4545 4545
						   4545 4545 4545>;
		oplus_spec,wls-ffc-icl-ma = <1150 1150 1550
					     800  1050 1500>;
		oplus_spec,wls-ffc-fcc-ma = <1500 1500 2070
					     1050 1400 1970>;
		oplus_spec,wls-ffc-fcc-cutoff-ma = <1300 1300 1870
						    950 1300 1870>;
		oplus_spec,vbat_uv_thr_mv = <3000>;
		oplus_spec,vbat_charging_uv_thr_mv = <2900>;
		oplus_spec,vbat_charging_uv_delata_mv = <0>;

		/*If use subboard NTC as battery temp, config it as 20, otherwise 0 */
		oplus_spec,tbatt_power_off_cali_temp = <0>;
		oplus_spec,poweroff_high_batt_temp = <720>;
		oplus_spec,poweroff_emergency_batt_temp = <770>;
		oplus,vooc_show_ui_soc_decimal;
		oplus,ui_soc_decimal_speedmin = <20>;
		oplus,gauge_stuck_jump_support;
		oplus,gauge_stuck_threshold = <15>;
		oplus,gauge_stuck_time = <50>;
		oplus,hidden_soc_switch;
		oplus,reserve_chg_soc = <2>;
		oplus,hidden_soc_percent = <20>;
	};

	oplus_monitor: oplus,monitor {
		compatible = "oplus,monitor";
		oplus,topic-update-interval = <60000>;

		track,fast_chg_break_t_thd = <1400>;
		track,general_chg_break_t_thd = <300>;
		track,voocphy_type = <TRACK_AP_SINGLE_CP_VOOCPHY>;
		track,wired_max_power = <120000>;
		track,wired_fast_chg_scheme = <0>;

		track,gauge_status_ctrl;
		track,nominal_qmax1 = <5623>;
		track,nominal_fcc1 = <5189>;
		track,external_gauge_num = <1>;

		track,sili_cc_term_vol_curve = <400 3300 800 3400 1200 3500 10000 3600>;
		track,gauge_max_cell_vol = <4600>;
		track,gauge_max_charge_curr = <13000>;
		track,gauge_max_dischg_curr = <6000>;
		track,gauge_min_cell_temp = <30>;
		track,gauge_max_cell_temp = <70>;
		track,gauge_firmware_term_volt = <3100>;
		track,gauge_lifetime_support;

		oplus,chg_into_liquid;
		oplus,chg_into_liquid_cc_disconnect = <10>;
		oplus,chg_into_liquid_total_time = <5000>;
		oplus,chg_into_liquid_max_interval_time = <700>;
	};

	oplus_vooc: oplus,vooc {
		compatible = "oplus,vooc";
		oplus,vooc_ic = <&oplus_virtual_vphy>;

		oplus_spec,vooc_soc_range = <50 75 85>;

		oplus,vooc_data_width = <7>;
		oplus,vooc_curr_max = <CURR_LIMIT_7BIT_11_5A>;
		oplus,support_vooc_by_normal_charger_path;
		oplus,vooc_project = <14>;
		oplus,vooc_curr_table_type = <VOOC_CURR_TABLE_2_0>;
		oplus,vooc_power_max_w = <120>;
		oplus,voocphy_support = <2>;
		oplus,support_fake_vooc_check;

		oplus,smart_chg_bcc_support;
		oplus,subboard_ntc_abnormal_current = <7300>;

		oplus,abnormal_adapter_current = <CURR_LIMIT_7BIT_11_5A CURR_LIMIT_7BIT_11_5A
						CURR_LIMIT_7BIT_5_0A CURR_LIMIT_7BIT_5_0A
						CURR_LIMIT_7BIT_4_0A CURR_LIMIT_7BIT_4_0A
						CURR_LIMIT_7BIT_3_0A CURR_LIMIT_7BIT_3_0A
						CURR_LIMIT_7BIT_2_0A CURR_LIMIT_7BIT_2_0A>;

		oplus,abnormal_over_80w_adapter_current = <CURR_LIMIT_7BIT_11_5A CURR_LIMIT_7BIT_11_5A
						CURR_LIMIT_7BIT_7_0A CURR_LIMIT_7BIT_7_0A
						CURR_LIMIT_7BIT_6_0A CURR_LIMIT_7BIT_6_0A
						CURR_LIMIT_7BIT_5_0A CURR_LIMIT_7BIT_5_0A
						CURR_LIMIT_7BIT_4_0A CURR_LIMIT_7BIT_4_0A
						CURR_LIMIT_7BIT_3_0A CURR_LIMIT_7BIT_3_0A
						CURR_LIMIT_7BIT_2_0A CURR_LIMIT_7BIT_2_0A>;

		/* first data is strategy used temp type */
		oplus,general_strategy_name = "cgcl";
		oplus,general_strategy_data = < OPLUS_STRATEGY_USE_SHELL_TEMP
						0   380 CURR_LIMIT_7BIT_11_5A 1 0
						370 400 CURR_LIMIT_7BIT_8_0A 2 0
						390 420 CURR_LIMIT_7BIT_7_0A 3 1
						410 430 CURR_LIMIT_7BIT_4_0A 4 2
						420 440 CURR_LIMIT_7BIT_3_0A 4 3 >;


		oplus,plc_strategy-data = <&buck_simple_strategy &svooc_simple_strategy &vooc_simple_strategy>;
		oplus,plc_strategy-names = "default", "svooc", "vooc";

		oplus_virtual_vphy: oplus,virtual_vphy {
			compatible = "oplus,virtual_vphy";
			oplus,vphy_ic = <&master_vphy_sc8517>;
			oplus,dpdm_switch_ic = <&oplus_virtual_dpdm_switch>;

			oplus,ic_type = <OPLUS_CHG_IC_VIRTUAL_VPHY>;
			oplus,ic_index = <0>;
		};
	};
	oplus_smart_charge: oplus,smart_charge {
		compatible = "oplus,smart_charge";
		oplus,smart_chg_soh_support;
		oplus,quick_mode_gain_support;
	};

	oplus_chg_quirks: oplus,chg_quirks {
		compatible = "oplus,chg_quirks";
	};
	oplus_retention_charge: oplus,retention_charge {
		compatible = "oplus,retention_charge";
		oplus,topic-update-interval = <5000>;
		oplus,support_retention_name = "oplus_retention_quirks";
	};

	oplus_cpa: oplus,cpa {
		compatible = "oplus,cpa";
		oplus,protocol_list = <CHG_PROTOCOL_VOOC 120
				       CHG_PROTOCOL_PPS  33
				       CHG_PROTOCOL_PD 18
				       CHG_PROTOCOL_QC 18>;
		oplus,default_protocol_list = <CHG_PROTOCOL_VOOC
					       CHG_PROTOCOL_PPS
					       CHG_PROTOCOL_PD>;
		oplus,cpa_region_cfg_power_pps {
			oplus,region_id = /bits/ 8 <0x44 0x83 0x5A>;
			oplus,protocol_list = <CHG_PROTOCOL_VOOC 120
				       CHG_PROTOCOL_PPS  55
				       CHG_PROTOCOL_PD 18
				       CHG_PROTOCOL_QC 18>;
		oplus,default_protocol_list = <CHG_PROTOCOL_VOOC
					       CHG_PROTOCOL_PPS
					       CHG_PROTOCOL_PD>;
		};
	};

	oplus_virtual_cp: oplus,virtual_cp {
		compatible = "oplus,virtual_cp";

		oplus,ic_type = <OPLUS_CHG_IC_VIRTUAL_CP>;
		oplus,ic_index = <0>;

		oplus,cp_ic = <&oplus_sc8517_cp>;
		oplus,input_curr_max_ma = <12300>;

		oplus,cp_ic_connect = <OPLUS_CHG_IC_CONNECT_PARALLEL>;
		oplus,main_cp = <0>;
	};

	oplus_virtual_dpdm_switch: oplus,virtual_dpdm_switch {
		compatible = "oplus,virtual_dpdm_switch";

		oplus,ic_type = <OPLUS_CHG_IC_MISC>;
		oplus,ic_index = <0>;

		oplus,use_audio_switch;
	};
};

&i2c1 {
	status = "okay";
	clock-frequency = <400000>;
	master_vphy_sc8517: sc8517-charger@69{
		status = "okay";
		compatible = "sc,sc8517-master";
		reg = <0x69>;

		oplus,irq_gpio = <&pio 83 0x00>;

		pinctrl-names = "charging_inter_active", "charging_inter_sleep";
		pinctrl-0 = <&charging_inter_active>;
		pinctrl-1 = <&charging_inter_sleep>;

		oplus,ic_type = <OPLUS_CHG_IC_VPHY>;
		oplus,ic_index = <0>;
		oplus,vooc-version = <VOOC_VERSION_5_0>;

		oplus_spec,external_gauge_support;
		oplus_spec,voocphy_bidirect_cp_support;
		oplus_spec,voocphy_current_default = <109>;

		oplus_spec,svooc_cool_down_current_limit = <109 15 15 20 25 30 35 40 45 50 55 60 63 65 70 75 80 85 109>;
		oplus_spec,vooc_cool_down_current_limit = <60 20 20 20 30 40 50 60>;
		oplus_spec,vooc_little_cold_full_voltage = <4570>;
		oplus_spec,vooc_cool_full_voltage = <4570>;
		oplus_spec,vooc_little_cool_full_voltage = <4570>;
		oplus_spec,vooc_little_cool_high_full_voltage = <4570>;
		oplus_spec,vooc_warm_full_voltage = <4100>;
		oplus_spec,vooc_1time_full_voltage = <4580>;
		oplus_spec,vooc_ntime_full_voltage = <4570>;
		oplus_spec,low_curr_full_t1 = <120>;
		oplus_spec,low_curr_full_t2 = <350>;
		oplus_spec,low_curr_full_t3 = <430>;
		oplus_spec,range1_low_curr_full = <1350 4540
						1250 4535
						1150 4520
						1050 4510
						950 4500>;
		oplus_spec,range2_low_curr_full = <1450 4540
						1350 4535
						1250 4520
						1150 4510
						1050 4500>;

		oplus_spec,vooc_multistep_initial_batt_temp = <1000>;
		oplus_spec,vooc_little_cool_temp = <160>;
		oplus_spec,vooc_little_cool_high_temp = <210>;
		oplus_spec,vooc_cool_temp = <120>;
		oplus_spec,vooc_little_cold_temp = <50>;
		oplus_spec,vooc_normal_low_temp = <350>;
		oplus_spec,vooc_strategy_normal_current = <100>;
		oplus_spec,vooc_normal_to_little_cool_current = <100>;
		oplus_spec,vooc_over_high_temp = <510>;
		oplus_spec,vooc_low_temp = <50>;
		oplus_spec,vooc_high_temp = <500>;
		oplus_spec,vooc_low_soc = <0>;
		oplus_spec,vooc_high_soc = <95>;
		oplus_spec,vooc_normal_high_temp = <440>;
		oplus_spec,vooc_warm_vol_thr = <4000>;
		oplus_spec,vooc_warm_soc_thr = <55>;
		oplus_spec,impedance_calculation_newmethod;
		oplus_spec,svooc_circuit_r_l = <0x18>;
		oplus_spec,svooc_circuit_r_h = <0x2>;/* 65 mR */
		oplus_spec,fastchg_timeout_time_init = <172280>;
		oplus_spec,voocphy_ibat_over_current = <12300>;
		oplus_spec,voocphy_cp_max_ibus = <12300>;
		oplus_spec,voocphy_svooc_cp_max_ibus = <3500>;
		oplus_spec,voocphy_vooc_cp_max_ibus = <3500>;
		oplus_spec,batt_pwd_curr_thd1 = <6300>;
		oplus_spec,batt_pwd_vol_thd1 = <4570>;

		oplus_spec,voocphy_req_freq = <1920000 2956800 2956800 3302400>;
		oplus_spec,voocphy_freq_mincore = <1920000>;
		oplus_spec,voocphy_freq_midcore = <2956800>;
		oplus_spec,voocphy_freq_maxcore = <2956800>;
		oplus_spec,voocphy_current_change_timeout = <100>;
		oplus_spec,copycat_vooc_support;
		oplus,abnormal_adapter_current = <CURR_LIMIT_7BIT_11_5A CURR_LIMIT_7BIT_11_5A
						  CURR_LIMIT_7BIT_5_0A CURR_LIMIT_7BIT_5_0A
						  CURR_LIMIT_7BIT_4_0A CURR_LIMIT_7BIT_4_0A
						  CURR_LIMIT_7BIT_3_0A CURR_LIMIT_7BIT_3_0A
						  CURR_LIMIT_7BIT_2_0A CURR_LIMIT_7BIT_2_0A>;

		svooc_batt_sys_curve = <1 1 0 1 1 0 1	// 10900mA
					1 0 1 1 1 0 0	// 4324mV
					0 0 1 0 1 0 0	// 2000mA
					1 1 1 0 1 1 1	// 4594mV
					0 0 0 1 1 0 0	// 1200mA
					1 1 1 0 1 1 1>; // 4594mV

		vooc_batt_sys_curve =  <0 1 0 1 1 0 1 	// 4500mA
					0 0 0 0 0 0 1	// 3414mV
					0 0 1 0 1 0 0	// 2000mA
					1 1 1 0 1 1 1	// 4594mV
					0 0 0 1 0 1 0	// 1000mA
					1 1 1 0 1 1 1>; // 4594mV

		oplus_spec,soc_range = <0 20 35 55 75 85 90>;
		svooc_lcf_strategy {
			oplus,temp_type = <OPLUS_STRATEGY_USE_SHELL_TEMP>;
			oplus,temp_range = <0 50 120 160 200 350 440>;
			strategy_temp_range_curves {
				strategy_temp_range_t0 =	<500 4570 0
								 475 4560 0
								 450 4550 0
								 425 4540 0
								 400 4530 1>;
				strategy_temp_range_t1 =	<600 4570 0
								 565 4565 0
								 530 4550 0
								 495 4540 0
								 460 4530 1>;
				strategy_temp_range_t2 =	<750 4570 0
								 705 4565 0
								 660 4550 0
								 615 4540 0
								 570 4530 1>;
				strategy_temp_range_t3 =	<950 4570 0
								 900 4565 0
								 800 4550 0
								 700 4540 0
								 550 4530 1>;
				strategy_temp_range_t4 =	<1350 4570 0
								 1300 4565 0
								 1200 4550 0
								 1100 4540 0
								 950  4530 1>;
				strategy_temp_range_t5 =	<2150 4570 0
								 2100 4565 0
								 2000 4550 0
								 1900 4540 0
								 1750 4530 1>;
			};
		};
		svooc_charge_strategy {
			strategy_soc_0_to_50 { /* 0 ~ 20 */
				strategy_temp_little_cold =	<4150 25 0 0 0
								4150 30 0 0 0
								4480 25 0 0 0
								4530 20 0 0 0
								4530 15 0 0 0
								4530 10 0 0 0
								4540  7 1 0 0>;
				strategy_temp_cool =		<4150 25 0 0 0
								4150 20 0 0 0
								4510 15 0 0 0
								4510 10 0 0 0
								4560  8 0 0 0
								4570  6 1 0 0>;
				strategy_temp_little_cool =	<4150 31 0 0 0
								4150 30 0 0 0
								4330 25 0 0 0
								4330 20 0 0 0
								4560 15 0 0 0
								4560 10 0 0 0
								4570  8 1 0 0>;
				strategy_temp_little_cool_high =<4150 63 0 0 0
								4150 60 0 0 0
								4150 55 0 0 0
								4150 50 0 0 0
								4280 47 0 0 0
								4280 45 0 0 0
								4280 40 0 0 0
								4510 38 0 0 0
								4510 35 0 0 0
								4560 31 0 0 0
								4560 30 0 0 0
								4560 25 0 0 0
								4560 20 0 0 0
								4560 15 0 0 0
								4570 10 1 0 0>;
				strategy_temp_normal_low =	<4080 109 0 60 0
								4220 90 0 360 0
								4370 79 0 0 0
								4370 75 0 0 0
								4370 70 0 0 0
								4370 65 0 0 0
								4470 61 0 0 0
								4470 60 0 0 0
								4470 55 0 0 0
								4470 50 0 0 0
								4530 45 0 0 0
								4530 40 0 0 0
								4560 36 0 0 0
								4560 35 0 0 0
								4560 30 0 0 0
								4560 25 0 0 0
								4560 20 0 0 0
								4560 15 0 0 0
								4570 14 1 0 0>;
				strategy_temp_normal_high =	<4080 109 0 60 0
								4220 90 0 360 0
								4370 79 0 0 0
								4370 75 0 0 0
								4370 70 0 0 0
								4370 65 0 0 0
								4470 61 0 0 0
								4470 60 0 0 0
								4470 55 0 0 0
								4470 50 0 0 0
								4520 45 0 0 0
								4520 40 0 0 0
								4560 36 0 0 0
								4560 35 0 0 0
								4560 30 0 0 0
								4560 25 0 0 0
								4570 22 1 0 0>;
				strategy_temp_warm =		<4090 18 0 0 0
								4090 15 0 0 0
								4090 10 0 0 0
								4100 5 1 0 0>;
			};
			strategy_soc_0_to_50_mid { /* 21 ~ 35 */
				strategy_temp_little_cold =	<4150 31 0 0 0
								4150 30 0 0 0
								4480 25 0 0 0
								4530 20 0 0 0
								4530 15 0 0 0
								4530 10 0 0 0
								4540  7 1 0 0>;
				strategy_temp_cool =		<4150 25 0 0 0
								4150 20 0 0 0
								4510 15 0 0 0
								4510 10 0 0 0
								4560  8 0 0 0
								4570  6 1 0 0>;
				strategy_temp_little_cool =	<4150 31 0 0 0
								4150 30 0 0 0
								4330 25 0 0 0
								4330 20 0 0 0
								4560 15 0 0 0
								4560 10 0 0 0
								4570  8 1 0 0>;
				strategy_temp_little_cool_high =<4150 63 0 0 0
								4150 60 0 0 0
								4150 55 0 0 0
								4150 50 0 0 0
								4280 47 0 0 0
								4280 45 0 0 0
								4280 40 0 0 0
								4510 38 0 0 0
								4510 35 0 0 0
								4560 31 0 0 0
								4560 30 0 0 0
								4560 25 0 0 0
								4560 20 0 0 0
								4560 15 0 0 0
								4570 10 1 0 0>;
				strategy_temp_normal_low =	<4080 109 0 60 0
								4220 90 0 360 0
								4370 79 0 0 0
								4370 75 0 0 0
								4370 70 0 0 0
								4370 65 0 0 0
								4470 61 0 0 0
								4470 60 0 0 0
								4470 55 0 0 0
								4470 50 0 0 0
								4530 45 0 0 0
								4530 40 0 0 0
								4560 36 0 0 0
								4560 35 0 0 0
								4560 30 0 0 0
								4560 25 0 0 0
								4560 20 0 0 0
								4560 15 0 0 0
								4570 14 1 0 0>;
				strategy_temp_normal_high =	<4080 109 0 60 0
								4220 90 0 360 0
								4370 79 0 0 0
								4370 75 0 0 0
								4370 70 0 0 0
								4370 65 0 0 0
								4470 61 0 0 0
								4470 60 0 0 0
								4470 55 0 0 0
								4470 50 0 0 0
								4520 45 0 0 0
								4520 40 0 0 0
								4560 36 0 0 0
								4560 35 0 0 0
								4560 30 0 0 0
								4560 25 0 0 0
								4570 22 1 0 0>;
				strategy_temp_warm =		<4090 18 0 0 0
								4090 15 0 0 0
								4090 10 0 0 0
								4100 5 1 0 0>;
			};

			strategy_soc_0_to_50_high { /* 36 ~ 55 */
				strategy_temp_little_cold =	<4150 31 0 0 0
								4150 30 0 0 0
								4480 25 0 0 0
								4530 20 0 0 0
								4530 15 0 0 0
								4530 10 0 0 0
								4540  7 1 0 0>;
				strategy_temp_cool =		<4150 25 0 0 0
								4150 20 0 0 0
								4510 15 0 0 0
								4510 10 0 0 0
								4560  8 0 0 0
								4570  6 1 0 0>;
				strategy_temp_little_cool =	<4150 31 0 0 0
								4150 30 0 0 0
								4330 25 0 0 0
								4330 20 0 0 0
								4560 15 0 0 0
								4560 10 0 0 0
								4570  8 1 0 0>;
				strategy_temp_little_cool_high =<4150 63 0 0 0
								4150 60 0 0 0
								4150 55 0 0 0
								4150 50 0 0 0
								4280 47 0 0 0
								4280 45 0 0 0
								4280 40 0 0 0
								4510 38 0 0 0
								4510 35 0 0 0
								4560 31 0 0 0
								4560 30 0 0 0
								4560 25 0 0 0
								4560 20 0 0 0
								4560 15 0 0 0
								4570 10 1 0 0>;
				strategy_temp_normal_low =	<4080 109 0 60 0
								4220 90 0 360 0
								4370 79 0 0 0
								4370 75 0 0 0
								4370 70 0 0 0
								4370 65 0 0 0
								4470 61 0 0 0
								4470 60 0 0 0
								4470 55 0 0 0
								4470 50 0 0 0
								4530 45 0 0 0
								4530 40 0 0 0
								4560 36 0 0 0
								4560 35 0 0 0
								4560 30 0 0 0
								4560 25 0 0 0
								4560 20 0 0 0
								4560 15 0 0 0
								4570 14 1 0 0>;
				strategy_temp_normal_high =	<4080 109 0 60 0
								4220 90 0 360 0
								4370 79 0 0 0
								4370 75 0 0 0
								4370 70 0 0 0
								4370 65 0 0 0
								4470 61 0 0 0
								4470 60 0 0 0
								4470 55 0 0 0
								4470 50 0 0 0
								4520 45 0 0 0
								4520 40 0 0 0
								4560 36 0 0 0
								4560 35 0 0 0
								4560 30 0 0 0
								4560 25 0 0 0
								4570 22 1 0 0>;
				strategy_temp_warm =		<4090 18 0 0 0
								4090 15 0 0 0
								4090 10 0 0 0
								4100 5 1 0 0>;
			};

			strategy_soc_50_to_75 { /* 56 ~ 75 */
				strategy_temp_little_cold =	<4150 31 0 0 0
								4150 30 0 0 0
								4480 25 0 0 0
								4530 20 0 0 0
								4530 15 0 0 0
								4530 10 0 0 0
								4540  7 1 0 0>;
				strategy_temp_cool =		<4150 25 0 0 0
								4150 20 0 0 0
								4510 15 0 0 0
								4510 10 0 0 0
								4560  8 0 0 0
								4570  6 1 0 0>;
				strategy_temp_little_cool =	<4150 31 0 0 0
								4150 30 0 0 0
								4330 25 0 0 0
								4330 20 0 0 0
								4560 15 0 0 0
								4560 10 0 0 0
								4570  8 1 0 0>;
				strategy_temp_little_cool_high =<4280 40 0 0 0
								4510 38 0 0 0
								4510 35 0 0 0
								4560 31 0 0 0
								4560 30 0 0 0
								4560 25 0 0 0
								4560 20 0 0 0
								4560 15 0 0 0
								4570 10 1 0 0>;
				strategy_temp_normal_low =	<4530 45 0 0 0
								4530 40 0 0 0
								4560 36 0 0 0
								4560 35 0 0 0
								4560 30 0 0 0
								4560 25 0 0 0
								4560 20 0 0 0
								4560 15 0 0 0
								4570 14 1 0 0>;
				strategy_temp_normal_high =	<4470 50 0 0 0
								4520 45 0 0 0
								4520 40 0 0 0
								4560 36 0 0 0
								4560 35 0 0 0
								4560 30 0 0 0
								4560 25 0 0 0
								4570 22 1 0 0>;
				strategy_temp_warm =		<4120 14 0 0 0
								4130 10 1 0 0>;
			};

			strategy_soc_75_to_85 { /* 76 ~ 85 */
				strategy_temp_little_cold =	<4150 31 0 0 0
								4150 30 0 0 0
								4480 25 0 0 0
								4530 20 0 0 0
								4530 15 0 0 0
								4530 10 0 0 0
								4540  7 1 0 0>;
				strategy_temp_cool =		<4150 25 0 0 0
								4150 20 0 0 0
								4510 15 0 0 0
								4510 10 0 0 0
								4560  8 0 0 0
								4570  6 1 0 0>;
				strategy_temp_little_cool =	<4150 30 0 0 0
								4330 25 0 0 0
								4330 20 0 0 0
								4560 15 0 0 0
								4560 10 0 0 0
								4570  8 1 0 0>;
				strategy_temp_little_cool_high =<4560 30 0 0 0
								4560 25 0 0 0
								4560 20 0 0 0
								4560 15 0 0 0
								4570 10 1 0 0>;
				strategy_temp_normal_low =	<4560 35 0 0 0
								4560 30 0 0 0
								4560 25 0 0 0
								4560 20 0 0 0
								4560 15 0 0 0
								4570 14 1 0 0>;
				strategy_temp_normal_high =	<4560 35 0 0 0
								4560 30 0 0 0
								4560 25 0 0 0
								4570 22 1 0 0>;
				strategy_temp_warm =		<4120 14 0 0 0
								4130 10 1 0 0>;
			};
			strategy_soc_85_to_90 { /* 86 ~ 95 */
				strategy_temp_little_cold =	<4150 10 0 0 0
								4150  5 1 0 0>;
				strategy_temp_cool =		<4510 15 0 0 0
								4510 10 0 0 0
								4560  8 0 0 0
								4570  6 1 0 0>;
				strategy_temp_little_cool =	<4560 15 0 0 0
								4560 10 0 0 0
								4570  8 1 0 0>;
				strategy_temp_little_cool_high = <4560 15 0 0 0
								4570 10 1 0 0>;
				strategy_temp_normal_low =	<4560 20 0 0 0
								4560 15 0 0 0
								4570 14 1 0 0>;
				strategy_temp_normal_high =	<4570 22 1 0 0>;
				strategy_temp_warm =		<4120 14 0 0 0
								4130 10 1 0 0>;
			};
		};

		vooc_charge_strategy {
			strategy_soc_0_to_50 {
				strategy_temp_little_cold =	<4430 20 1 0 0>;
				strategy_temp_cool =		<4420 30 0 0 0
								 4430 20 1 0 0>;
				strategy_temp_little_cool =	<4475 30 0 0 0
								 4480 20 1 0 0>;
				strategy_temp_little_cool_high = <4475 30 0 0 0
								 4480 20 1 0 0>;
				strategy_temp_normal_low =	<4475 30 0 0 0
								 4480 20 1 0 0>;
				strategy_temp_normal_high =	<4475 30 0 0 0
								 4480 20 1 0 0>;
				strategy_temp_warm =		<4130 24 1 0 0>;
			};
			strategy_soc_0_to_50_mid {
				strategy_temp_little_cold =	<4430 20 1 0 0>;
				strategy_temp_cool =		<4420 30 0 0 0
								 4430 20 1 0 0>;
				strategy_temp_little_cool =	<4475 30 0 0 0
								 4480 20 1 0 0>;
				strategy_temp_little_cool_high = <4475 30 0 0 0
								 4480 20 1 0 0>;
				strategy_temp_normal_low =	<4475 30 0 0 0
								 4480 20 1 0 0>;
				strategy_temp_normal_high =	<4475 30 0 0 0
								 4480 20 1 0 0>;
				strategy_temp_warm =		<4130 24 1 0 0>;
			};
			strategy_soc_0_to_50_high {
				strategy_temp_little_cold = 	<4430 20 1 0 0>;
				strategy_temp_cool =		<4420 30 0 0 0
								 4430 20 1 0 0>;
				strategy_temp_little_cool =	<4475 30 0 0 0
								 4480 20 1 0 0>;
				strategy_temp_little_cool_high = <4475 30 0 0 0
								 4480 20 1 0 0>;
				strategy_temp_normal_low =	<4475 30 0 0 0
								 4480 20 1 0 0>;
				strategy_temp_normal_high =	<4475 30 0 0 0
								 4480 20 1 0 0>;
				strategy_temp_warm =		<4130 24 1 0 0>;
			};

			strategy_soc_50_to_75 {
				strategy_temp_little_cold =	<4430 20 1 0 0>;
				strategy_temp_cool =		<4420 30 0 0 0
								 4430 20 1 0 0>;
				strategy_temp_little_cool =	<4475 30 0 0 0
								 4480 20 1 0 0>;
				strategy_temp_little_cool_high = <4475 30 0 0 0
								 4480 20 1 0 0>;
				strategy_temp_normal_low =	<4475 30 0 0 0
								 4480 20 1 0 0>;
				strategy_temp_normal_high =	<4475 30 0 0 0
								 4480 20 1 0 0>;
				strategy_temp_warm =		<4130 24 1 0 0>;
			};

			strategy_soc_75_to_85 {
				strategy_temp_little_cold =	<4430 20 1 0 0>;
				strategy_temp_cool =		<4430 20 1 0 0>;
				strategy_temp_little_cool =	<4480 20 1 0 0>;
				strategy_temp_little_cool_high = <4480 20 1 0 0>;
				strategy_temp_normal_low =	<4475 30 0 0 0
								 4480 20 1 0 0>;
				strategy_temp_normal_high =	<4475 30 0 0 0
								 4480 20 1 0 0>;
				strategy_temp_warm =		<4130 24 1 0 0>;
			};

			strategy_soc_85_to_90 {
				strategy_temp_little_cold =	<4430 20 1 0 0>;
				strategy_temp_cool =		<4430 20 1 0 0>;
				strategy_temp_little_cool =	<4480 20 1 0 0>;
				strategy_temp_little_cool_high = <4480 20 1 0 0>;
				strategy_temp_normal_low =	<4480 20 1 0 0>;
				strategy_temp_normal_high =	<4480 20 1 0 0>;
				strategy_temp_warm =		<4130 24 1 0 0>;
			};
		};

		oplus_sc8517_cp: oplus,sc8517_cp {
			oplus,ic_type = <OPLUS_CHG_IC_CP>;
			oplus,ic_index = <0>;
		};
	};
};


&i2c1 {
	pinctrl-names = "i2c-state", "output-low-state";
	pinctrl-0 = <&i2c1_i2c_state>;
	pinctrl-1 = <&i2c1_output_low_state>;
};

&pio {
	i2c1_i2c_state: i2c1_sda_i2c_state {
		pins_cmd_dat {
			pinmux = <PINMUX_GPIO100__FUNC_SCL1>,
			<PINMUX_GPIO101__FUNC_SDA1>;
			bias-pull-up;
		};
	};
	i2c1_output_low_state: i2c1_sda_output_low_state {
		pins_cmd_dat {
			pinmux = <PINMUX_GPIO100__FUNC_GPIO100>,
			<PINMUX_GPIO101__FUNC_GPIO101>;
			output-low;
		};
	};
};
&i2c5 {
	status = "okay";
	clock-frequency = <400000>;

	byb_tps6128xd: byb-tps6128xd@75 {
		status = "okay";
		compatible = "oplus,byb-tps6128xd";
		reg = <0x75>;
		oplus,ic_type = <OPLUS_CHG_IC_BOOST>;
		oplus,ic_index = <0>;
		oplus,vout-mv = <3350>;
		oplus,ilim-ma = <4500>;
	};
};

&i2c12 {
	status = "okay";
	clock-frequency = <400000>;

	byb_tps6128xd_second: byb-tps6128xd@75 {
		status = "okay";
		compatible = "oplus,byb-tps6128xd";
		reg = <0x75>;
		oplus,ic_type = <OPLUS_CHG_IC_BOOST>;
		oplus,ic_index = <1>;
		oplus,vout-mv = <3350>;
		oplus,ilim-ma = <4500>;
	};
};
&charger {
	oplus_mtk_pps: oplus,mtk_pps {
		oplus,ic_type = <OPLUS_CHG_IC_PPS>;
		oplus,ic_index = <0>;
	};
};
&soc {
	oplus_virtual_pps: oplus,virtual_pps {
		compatible = "oplus,virtual_pps";
		oplus,ic_type = <OPLUS_CHG_IC_VIRTUAL_PPS>;
		oplus,ic_index = <0>;
		oplus,pps_ic = <&oplus_mtk_pps>;
	};
	oplus_pps_charge: oplus,pps_charge {
		compatible = "oplus,pps_charge";
		oplus,pps_ic = <&oplus_virtual_pps>;
		oplus,cp_ic = <&oplus_virtual_cp>;
		oplus,dpdm_switch_ic = <&oplus_virtual_dpdm_switch>;
		oplus,process_close_cp_item;
		oplus,target_vbus_mv = <11000>;
		oplus,curr_max_ma = <5000>;
		oplus,pps_enable_pps_status;
		oplus,pps_warm_allow_vol = <4000>;
		oplus,pps_warm_allow_soc = <55>;
		oplus,pps_strategy_normal_current = <5000>;
		oplus,pps_over_high_or_low_current = <5000>;
		oplus,pps_timeout_third = <17228>;
		oplus,pps_timeout_oplus = <17228>;
		oplus,pps_ibat_over_third = <6400>;
		oplus,pps_ibat_over_oplus = <6400>;
		oplus,pps_full_cool_sw_vbat = <4500>;
		oplus,pps_full_normal_sw_vbat = <4500>;
		oplus,pps_full_normal_hw_vbat = <4540>;
		oplus,pps_full_ffc_vbat = <4550>;
		oplus,pps_full_warm_vbat = <4100>;
		oplus,pps_full_cool_sw_vbat_third = <4500>;
		oplus,pps_full_normal_sw_vbat_third= <4500>;
		oplus,pps_full_normal_hw_vbat_third = <4540>;
		oplus,pps_current_change_timeout = <100>;
		oplus,pps_strategy_batt_high_temp = <405 420 430 395 410 425>;
		oplus,pps_strategy_high_current = <5000 4000 3000 5000 5000 4000>;
		oplus,pps_little_cool_high_temp = <210>;
		oplus,pps_low_temp = <50>;
		oplus,curve_strategy_name = "pps_ufcs_curve_v2";
		oplus,pps_charge_strategy_soc = <0 20 35 55 75 85 85>;
		oplus,pps_charge_strategy_temp = <50 50 120 160 350 440 510>;

		oplus,plc_strategy-data = <&pps_simple_strategy>;
		oplus,plc_strategy-names = "default";

		pps_charge_third_strategy {
			oplus,temp_type = <OPLUS_STRATEGY_USE_SHELL_TEMP>;
			oplus,soc_range = <0 20 35 55 75 85 90>;
			oplus,temp_range = <0 50 120 160 210 350 440 510>;
			strategy_soc_range_min { /* 0 ~ 20 */
				strategy_temp_little_cold =	<11000 4140 1300 0 0
								11000 4150 1000 1 0>;
				strategy_temp_cool =		<11000 4150 2500 0 0
								11000 4150 2000 0 0
								11000 4490 1500 0 0
								11000 4500 1000 1 0>;
				strategy_temp_little_cool =	<11000 4150 3100 0 0
								11000 4150 3000 0 0
								11000 4330 2500 0 0
								11000 4330 2000 0 0
								11000 4490 1500 0 0
								11000 4500 1000 1 0>;
				strategy_temp_little_cool_high = <11000 4150 5000 0 0
								11000 4280 4700 0 0
								11000 4280 4500 0 0
								11000 4280 4000 0 0
								11000 4490 3800 0 0
								11000 4490 3500 0 0
								11000 4490 3100 0 0
								11000 4490 3000 0 0
								11000 4490 2500 0 0
								11000 4490 2000 0 0
								11000 4490 1500 0 0
								11000 4500 1000 1 0>;
				strategy_temp_normal_low =	<11000 4470 5000 0 0
								11000 4490 4500 0 0
								11000 4490 4000 0 0
								11000 4490 3600 0 0
								11000 4490 3500 0 0
								11000 4490 3000 0 0
								11000 4490 2500 0 0
								11000 4490 2000 0 0
								11000 4490 1500 0 0
								11000 4500 1000 1 0>;
				strategy_temp_normal_high =	<11000 4460 5000 0 0
								11000 4465 4500 0 0
								11000 4465 4000 0 0
								11000 4465 3600 0 0
								11000 4465 3500 0 0
								11000 4465 3000 0 0
								11000 4465 2500 0 0
								11000 4465 2000 0 0
								11000 4465 1500 0 0
								11000 4475 1000 1 0>;
				strategy_temp_warm =		<11000 4090 1800 0 0
								11000 4090 1500 0 0
								11000 4100 1000 1 0>;
			};
			strategy_soc_range_low { /* 21 ~ 35 */
				strategy_temp_little_cold =	<11000 4140 1300 0 0
								11000 4150 1000 1 0>;
				strategy_temp_cool =		<11000 4150 2500 0 0
								11000 4150 2000 0 0
								11000 4490 1500 0 0
								11000 4500 1000 1 0>;
				strategy_temp_little_cool =	<11000 4150 3100 0 0
								11000 4150 3000 0 0
								11000 4330 2500 0 0
								11000 4330 2000 0 0
								11000 4490 1500 0 0
								11000 4500 1000 1 0>;
				strategy_temp_little_cool_high = <11000 4150 5000 0 0
								11000 4280 4700 0 0
								11000 4280 4500 0 0
								11000 4280 4000 0 0
								11000 4490 3800 0 0
								11000 4490 3500 0 0
								11000 4490 3100 0 0
								11000 4490 3000 0 0
								11000 4490 2500 0 0
								11000 4490 2000 0 0
								11000 4490 1500 0 0
								11000 4500 1000 1 0>;
				strategy_temp_normal_low =	<11000 4470 5000 0 0
								11000 4490 4500 0 0
								11000 4490 4000 0 0
								11000 4490 3600 0 0
								11000 4490 3500 0 0
								11000 4490 3000 0 0
								11000 4490 2500 0 0
								11000 4490 2000 0 0
								11000 4490 1500 0 0
								11000 4500 1000 1 0>;
				strategy_temp_normal_high =	<11000 4460 5000 0 0
								11000 4465 4500 0 0
								11000 4465 4000 0 0
								11000 4465 3600 0 0
								11000 4465 3500 0 0
								11000 4465 3000 0 0
								11000 4465 2500 0 0
								11000 4465 2000 0 0
								11000 4465 1500 0 0
								11000 4475 1000 1 0>;
				strategy_temp_warm =		<11000 4090 1800 0 0
								11000 4090 1500 0 0
								11000 4100 1000 1 0>;
			};
			strategy_soc_range_mid_low { /* 36 ~ 55 */
				strategy_temp_little_cold =	<11000 4140 1300 0 0
								11000 4150 1000 1 0>;
				strategy_temp_cool =		<11000 4150 2500 0 0
								11000 4150 2000 0 0
								11000 4490 1500 0 0
								11000 4500 1000 1 0>;
				strategy_temp_little_cool =	<11000 4150 3100 0 0
								11000 4150 3000 0 0
								11000 4330 2500 0 0
								11000 4330 2000 0 0
								11000 4490 1500 0 0
								11000 4500 1000 1 0>;
				strategy_temp_little_cool_high = <11000 4150 5000 0 0
								11000 4280 4700 0 0
								11000 4280 4500 0 0
								11000 4280 4000 0 0
								11000 4490 3800 0 0
								11000 4490 3500 0 0
								11000 4490 3100 0 0
								11000 4490 3000 0 0
								11000 4490 2500 0 0
								11000 4490 2000 0 0
								11000 4490 1500 0 0
								11000 4500 1000 1 0>;
				strategy_temp_normal_low =	<11000 4470 5000 0 0
								11000 4490 4500 0 0
								11000 4490 4000 0 0
								11000 4490 3600 0 0
								11000 4490 3500 0 0
								11000 4490 3000 0 0
								11000 4490 2500 0 0
								11000 4490 2000 0 0
								11000 4490 1500 0 0
								11000 4500 1000 1 0>;
				strategy_temp_normal_high =	<11000 4460 5000 0 0
								11000 4465 4500 0 0
								11000 4465 4000 0 0
								11000 4465 3600 0 0
								11000 4465 3500 0 0
								11000 4465 3000 0 0
								11000 4465 2500 0 0
								11000 4465 2000 0 0
								11000 4465 1500 0 0
								11000 4475 1000 1 0>;
				strategy_temp_warm =		<11000 4120 1800 0 0
								11000 4120 1500 0 0
								11000 4130 1000 1 0>;
			};
			strategy_soc_range_mid { /* 56 ~ 75 */
				strategy_temp_little_cold =	<11000 4140 1300 0 0
								11000 4150 1000 1 0>;
				strategy_temp_cool =		<11000 4150 2000 0 0
								11000 4490 1500 0 0
								11000 4500 1000 1 0>;
				strategy_temp_little_cool =	<11000 4150 3000 0 0
								11000 4330 2500 0 0
								11000 4330 2000 0 0
								11000 4490 1500 0 0
								11000 4500 1000 1 0>;
				strategy_temp_little_cool_high = <11000 4490 3000 0 0
								11000 4490 2500 0 0
								11000 4490 2000 0 0
								11000 4490 1500 0 0
								11000 4500 1000 1 0>;
				strategy_temp_normal_low =	<11000 4490 3500 0 0
								11000 4490 3000 0 0
								11000 4490 2500 0 0
								11000 4490 2000 0 0
								11000 4490 1500 0 0
								11000 4500 1000 1 0>;
				strategy_temp_normal_high =	<11000 4465 4000 0 0
								11000 4465 3600 0 0
								11000 4465 3500 0 0
								11000 4465 3000 0 0
								11000 4465 2500 0 0
								11000 4465 2000 0 0
								11000 4465 1500 0 0
								11000 4475 1000 1 0>;
				strategy_temp_warm =		<11000 4130 1000 1 0>;
			};
			strategy_soc_range_mid_high { /* 76 ~ 85 */
				strategy_temp_little_cold =	<11000 4140 1300 0 0
								11000 4150 1000 1 0>;
				strategy_temp_cool =		<11000 4490 1500 0 0
								11000 4500 1000 1 0>;
				strategy_temp_little_cool =	<11000 4330 2000 0 0
								11000 4490 1500 0 0
								11000 4500 1000 1 0>;
				strategy_temp_little_cool_high = <11000 4490 2000 0 0
								11000 4490 1500 0 0
								11000 4500 1000 1 0>;
				strategy_temp_normal_low =	<11000 4490 2500 0 0
								11000 4490 2000 0 0
								11000 4490 1500 0 0
								11000 4500 1000 1 0>;
				strategy_temp_normal_high =	<11000 4465 2500 0 0
								11000 4465 2000 0 0
								11000 4465 1500 0 0
								11000 4475 1000 1 0>;
				strategy_temp_warm =		<11000 4130 1000 1 0>;
			};
			strategy_soc_range_high { /* 86 ~ 90 */
				strategy_temp_little_cold =	<11000 4150 1000 1 0>;
				strategy_temp_cool =		<11000 4500 1000 1 0>;
				strategy_temp_little_cool =	<11000 4500 1000 1 0>;
				strategy_temp_little_cool_high = <11000 4500 1000 1 0>;
				strategy_temp_normal_low =	<11000 4500 1000 1 0>;
				strategy_temp_normal_high =	<11000 4475 1000 1 0>;
				strategy_temp_warm =		<11000 4130 1000 1 0>;
			};
		};
		pps_charge_oplus_strategy {
			oplus,temp_type = <OPLUS_STRATEGY_USE_SHELL_TEMP>;
			oplus,soc_range = <0 20 35 55 75 85 90>;
			oplus,temp_range = <0 50 120 160 210 350 440 510>;
			strategy_soc_range_min { /* 0 ~ 20 */
				strategy_temp_little_cold =	<11000 4140 1300 0 0
								11000 4150 1000 1 0>;
				strategy_temp_cool =		<11000 4150 2500 0 0
								11000 4150 2000 0 0
								11000 4490 1500 0 0
								11000 4500 1000 1 0>;
				strategy_temp_little_cool =	<11000 4150 3100 0 0
								11000 4150 3000 0 0
								11000 4330 2500 0 0
								11000 4330 2000 0 0
								11000 4490 1500 0 0
								11000 4500 1000 1 0>;
				strategy_temp_little_cool_high = <11000 4150 5000 0 0
								11000 4280 4700 0 0
								11000 4280 4500 0 0
								11000 4280 4000 0 0
								11000 4490 3800 0 0
								11000 4490 3500 0 0
								11000 4490 3100 0 0
								11000 4490 3000 0 0
								11000 4490 2500 0 0
								11000 4490 2000 0 0
								11000 4490 1500 0 0
								11000 4500 1000 1 0>;
				strategy_temp_normal_low =	<11000 4470 5000 0 0
								11000 4490 4500 0 0
								11000 4490 4000 0 0
								11000 4490 3600 0 0
								11000 4490 3500 0 0
								11000 4490 3000 0 0
								11000 4490 2500 0 0
								11000 4490 2000 0 0
								11000 4490 1500 0 0
								11000 4500 1000 1 0>;
				strategy_temp_normal_high =	<11000 4470 5000 0 0
								11000 4465 4500 0 0
								11000 4465 4000 0 0
								11000 4465 3600 0 0
								11000 4465 3500 0 0
								11000 4465 3000 0 0
								11000 4465 2500 0 0
								11000 4465 2000 0 0
								11000 4465 1500 0 0
								11000 4475 1000 1 0>;
				strategy_temp_warm =		<11000 4090 1800 0 0
								11000 4090 1500 0 0
								11000 4100 1000 1 0>;
			};
			strategy_soc_range_low { /* 21 ~ 35 */
				strategy_temp_little_cold =	<11000 4140 1300 0 0
								11000 4150 1000 1 0>;
				strategy_temp_cool =		<11000 4150 2500 0 0
								11000 4150 2000 0 0
								11000 4490 1500 0 0
								11000 4500 1000 1 0>;
				strategy_temp_little_cool =	<11000 4150 3100 0 0
								11000 4150 3000 0 0
								11000 4330 2500 0 0
								11000 4330 2000 0 0
								11000 4490 1500 0 0
								11000 4500 1000 1 0>;
				strategy_temp_little_cool_high = <11000 4150 5000 0 0
								11000 4280 4700 0 0
								11000 4280 4500 0 0
								11000 4280 4000 0 0
								11000 4490 3800 0 0
								11000 4490 3500 0 0
								11000 4490 3100 0 0
								11000 4490 3000 0 0
								11000 4490 2500 0 0
								11000 4490 2000 0 0
								11000 4490 1500 0 0
								11000 4500 1000 1 0>;
				strategy_temp_normal_low =	<11000 4470 5000 0 0
								11000 4490 4500 0 0
								11000 4490 4000 0 0
								11000 4490 3600 0 0
								11000 4490 3500 0 0
								11000 4490 3000 0 0
								11000 4490 2500 0 0
								11000 4490 2000 0 0
								11000 4490 1500 0 0
								11000 4500 1000 1 0>;
				strategy_temp_normal_high =	<11000 4470 5000 0 0
								11000 4465 4500 0 0
								11000 4465 4000 0 0
								11000 4465 3600 0 0
								11000 4465 3500 0 0
								11000 4465 3000 0 0
								11000 4465 2500 0 0
								11000 4465 2000 0 0
								11000 4465 1500 0 0
								11000 4475 1000 1 0>;
				strategy_temp_warm =		<11000 4090 1800 0 0
								11000 4090 1500 0 0
								11000 4100 1000 1 0>;
			};
			strategy_soc_range_mid_low { /* 36 ~ 55 */
				strategy_temp_little_cold =	<11000 4140 1300 0 0
								11000 4150 1000 1 0>;
				strategy_temp_cool =		<11000 4150 2500 0 0
								11000 4150 2000 0 0
								11000 4490 1500 0 0
								11000 4500 1000 1 0>;
				strategy_temp_little_cool =	<11000 4150 3100 0 0
								11000 4150 3000 0 0
								11000 4330 2500 0 0
								11000 4330 2000 0 0
								11000 4490 1500 0 0
								11000 4500 1000 1 0>;
				strategy_temp_little_cool_high = <11000 4150 5000 0 0
								11000 4280 4700 0 0
								11000 4280 4500 0 0
								11000 4280 4000 0 0
								11000 4490 3800 0 0
								11000 4490 3500 0 0
								11000 4490 3100 0 0
								11000 4490 3000 0 0
								11000 4490 2500 0 0
								11000 4490 2000 0 0
								11000 4490 1500 0 0
								11000 4500 1000 1 0>;
				strategy_temp_normal_low =	<11000 4470 5000 0 0
								11000 4490 4500 0 0
								11000 4490 4000 0 0
								11000 4490 3600 0 0
								11000 4490 3500 0 0
								11000 4490 3000 0 0
								11000 4490 2500 0 0
								11000 4490 2000 0 0
								11000 4490 1500 0 0
								11000 4500 1000 1 0>;
				strategy_temp_normal_high =	<11000 4470 5000 0 0
								11000 4465 4500 0 0
								11000 4465 4000 0 0
								11000 4465 3600 0 0
								11000 4465 3500 0 0
								11000 4465 3000 0 0
								11000 4465 2500 0 0
								11000 4465 2000 0 0
								11000 4465 1500 0 0
								11000 4475 1000 1 0>;
				strategy_temp_warm =		<11000 4120 1800 0 0
								11000 4120 1500 0 0
								11000 4130 1000 1 0>;
			};
			strategy_soc_range_mid { /* 56 ~ 75 */
				strategy_temp_little_cold =	<11000 4140 1300 0 0
								11000 4150 1000 1 0>;
				strategy_temp_cool =		<11000 4150 2000 0 0
								11000 4490 1500 0 0
								11000 4500 1000 1 0>;
				strategy_temp_little_cool =	<11000 4150 3000 0 0
								11000 4330 2500 0 0
								11000 4330 2000 0 0
								11000 4490 1500 0 0
								11000 4500 1000 1 0>;
				strategy_temp_little_cool_high = <11000 4490 3000 0 0
								11000 4490 2500 0 0
								11000 4490 2000 0 0
								11000 4490 1500 0 0
								11000 4500 1000 1 0>;
				strategy_temp_normal_low =	<11000 4490 3500 0 0
								11000 4490 3000 0 0
								11000 4490 2500 0 0
								11000 4490 2000 0 0
								11000 4490 1500 0 0
								11000 4500 1000 1 0>;
				strategy_temp_normal_high =	<11000 4465 4000 0 0
								11000 4465 3600 0 0
								11000 4465 3500 0 0
								11000 4465 3000 0 0
								11000 4465 2500 0 0
								11000 4465 2000 0 0
								11000 4465 1500 0 0
								11000 4475 1000 1 0>;
				strategy_temp_warm =		<11000 4130 1000 1 0>;
			};
			strategy_soc_range_mid_high { /* 76 ~ 85 */
				strategy_temp_little_cold =	<11000 4140 1300 0 0
								11000 4150 1000 1 0>;
				strategy_temp_cool =		<11000 4490 1500 0 0
								11000 4500 1000 1 0>;
				strategy_temp_little_cool =	<11000 4330 2000 0 0
								11000 4490 1500 0 0
								11000 4500 1000 1 0>;
				strategy_temp_little_cool_high = <11000 4490 2000 0 0
								11000 4490 1500 0 0
								11000 4500 1000 1 0>;
				strategy_temp_normal_low =	<11000 4490 2500 0 0
								11000 4490 2000 0 0
								11000 4490 1500 0 0
								11000 4500 1000 1 0>;
				strategy_temp_normal_high =	<11000 4465 2500 0 0
								11000 4465 2000 0 0
								11000 4465 1500 0 0
								11000 4475 1000 1 0>;
				strategy_temp_warm =		<11000 4130 1000 1 0>;
			};
			strategy_soc_range_high { /* 86 ~ 90 */
				strategy_temp_little_cold =	<11000 4150 1000 1 0>;
				strategy_temp_cool =		<11000 4500 1000 1 0>;
				strategy_temp_little_cool =	<11000 4500 1000 1 0>;
				strategy_temp_little_cool_high = <11000 4500 1000 1 0>;
				strategy_temp_normal_low =	<11000 4500 1000 1 0>;
				strategy_temp_normal_high =	<11000 4475 1000 1 0>;
				strategy_temp_warm =		<11000 4130 1000 1 0>;
			};
		};
	};
};
&mt6379_typec {
	pd-data {
		pd,source-cap-ext = /bits/ 8 <0xcf 0x29 0x75 0x63
							      0x00 0x00 0x00 0x00
							      0x00 0x00 0x00 0x00
							      0x00 0x00 0x00 0x00
							      0x00 0x00 0x00 0x00
							      0x00 0x00 0x01 0x05
							      0x00>;

		pd,charging-policy = <0>;

		pd,source-pdo-data = <0x00019064>;/* Fixed, 5000mV, 1000mA*/

		pd,sink-pdo-size = <3>;
		pd,sink-pdo-data = <0x000190c8 0x0002d096 0xc0dc323c>;

		/* No DP, host + device */
		pd,id-vdo-data = <0xd14029cf 0x0 0x63750000
						  0x61000000 0x0 0x41000000>;
	};
	dpm-caps {
			// attempt-enter-dp-mode;
			attempt-discover-cable;
			attempt-discover-id;
			attempt-discover-svids;
	};
};
&soc {
	oplus_chg_plc: oplus,plc_charge {
		compatible = "oplus,plc_charge";
		oplus,plc_soc = <90>;
		oplus,plc_support_timeout;
		oplus,plc_strategy-data = <&buck_simple_strategy>;
		oplus,plc_strategy-names = "default";
		pps_simple_strategy: pps_simple_strategy {
			oplus,strategy_type = <PLC_STRATEGY_SIMPLE>;
			oplus,strategy_data {
				strategy_curr_ma = <1000 1500>;
			};
		};
		svooc_simple_strategy: svooc_simple_strategy {
			oplus,strategy_type = <PLC_STRATEGY_SIMPLE>;
			oplus,strategy_data {
				strategy_curr_ma = <1000 1500>;
			};
		};
		vooc_simple_strategy: vooc_simple_strategy {
			oplus,strategy_type = <PLC_STRATEGY_SIMPLE>;
			oplus,strategy_data {
				strategy_curr_ma = <2000 3000>;
			};
		};
		buck_simple_strategy: buck_simple_strategy {
			oplus,strategy_type = <PLC_STRATEGY_SIMPLE>;
		};
	};
};
